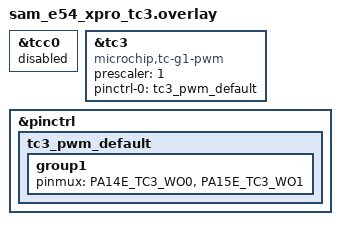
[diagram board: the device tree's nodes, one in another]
/*
 * Copyright (c) 2025 Microchip Technology Inc.
 *
 * SPDX-License-Identifier: Apache-2.0
 */

&tcc0 {
	status = "disabled";
};

&tc3 {
	status = "okay";
	compatible = "microchip,tc-g1-pwm";
	prescaler = <1>;
	#pwm-cells = <3>;
	pinctrl-0 = <&tc3_pwm_default>;
	pinctrl-names = "default";
};

&pinctrl {
	tc3_pwm_default: tc3_pwm_default {
		group1 {
			pinmux = <PA14E_TC3_WO0>,
				 <PA15E_TC3_WO1>;
		};
	};
};
